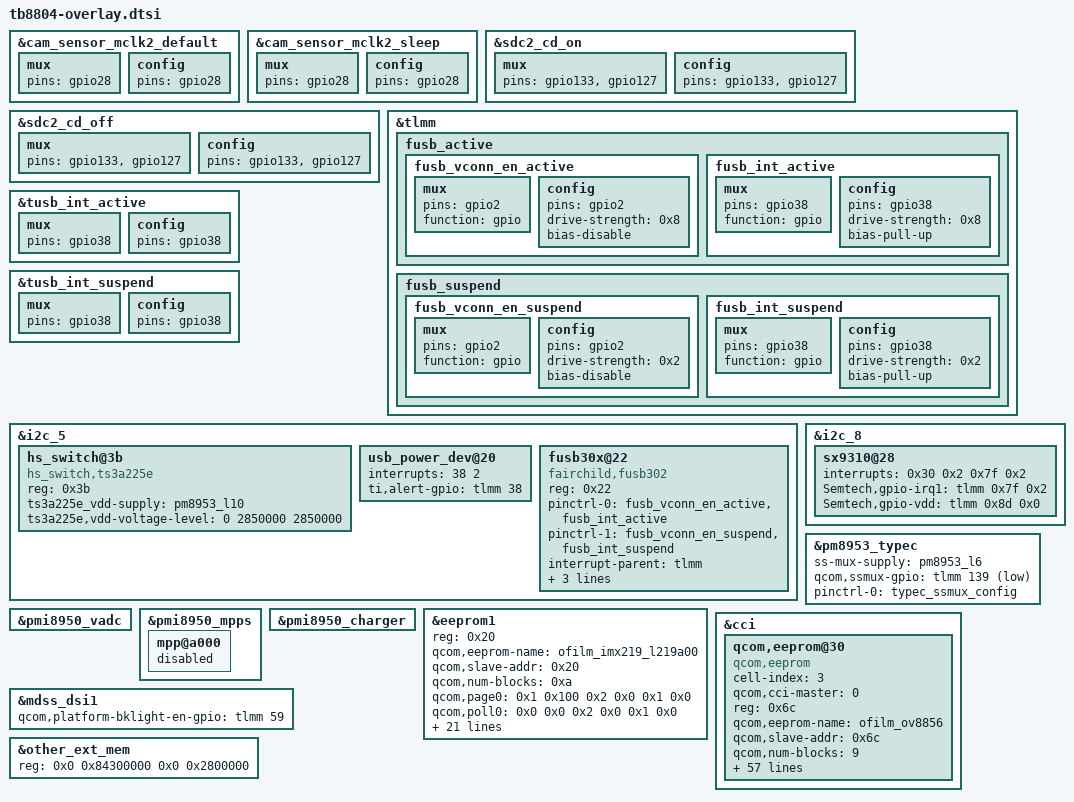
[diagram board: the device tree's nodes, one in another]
&cam_sensor_mclk2_default {
		mux {
				 pins = "gpio28";
		};
		config {
				 pins = "gpio28";
		};
};

&cam_sensor_mclk2_sleep {
		mux {
				 pins = "gpio28";
		};
		config {
				 pins = "gpio28";
		};


};

&sdc2_cd_on {
		mux {
				 pins = "gpio133", "gpio127";
		};
		config {
				 pins = "gpio133", "gpio127";
		};
};

&sdc2_cd_off {
		mux {
				 pins = "gpio133", "gpio127";
		};
		config {
				 pins = "gpio133", "gpio127";
		};
};


&tlmm {

		fusb_active {
				fusb_vconn_en_active: fusb_vconn_en_active {
						mux {
								pins = "gpio2";
								function = "gpio";
						};

						config {
								pins = "gpio2";
								drive-strength = <0x8>;
								bias-disable;
						};
				};

				fusb_int_active: fusb_int_active {

						mux {
								pins = "gpio38";
								function = "gpio";
						};

						config {
								pins = "gpio38";
								drive-strength = <0x8>;
								bias-pull-up;
						};
				};
		};

		fusb_suspend {

				fusb_vconn_en_suspend: fusb_vconn_en_suspend {
						mux {
								pins = "gpio2";
								function = "gpio";
						};

						config {
								pins = "gpio2";
								drive-strength = <0x2>;
								bias-disable;
						};
				};

				fusb_int_suspend: fusb_int_suspend {
						mux {
								pins = "gpio38";
								function = "gpio";
						};

						config {
								pins = "gpio38";
								drive-strength = <0x2>;
								bias-pull-up;
						};
				};
		};
};


&tusb_int_active {
		mux {
				pins = "gpio38";
		};
		config {
				pins = "gpio38";
		};
};

&tusb_int_suspend {
		mux {
				pins = "gpio38";
		};
		config {
				pins = "gpio38";
		};
};

&i2c_5 {
		status = "ok";
		hs_switch@3b {
				compatible = "hs_switch,ts3a225e";
				reg = <0x3b>;
				ts3a225e_vdd-supply = <&pm8953_l10>;
				ts3a225e,vdd-voltage-level = <0 2850000 2850000>;
		};
		usb_power_dev@20 {
				interrupts = <38 2>;
				ti,alert-gpio = <&tlmm 38 2>;
		};
		fusb30x@22 {
				compatible = "fairchild,fusb302";
				reg = <0x22>;
				status = "okay";
				pinctrl-names = "fusb_active", "fusb_suspend";
				pinctrl-0 = <&fusb_vconn_en_active &fusb_int_active>;
				pinctrl-1 = <&fusb_vconn_en_suspend &fusb_int_suspend>;
				interrupt-parent = <&tlmm>;
				interrupts = <38 2>;
				fairchild,vbus5v = <&pm8953_gpios 0x8 0x0>;
				fairchild,int_n = <&tlmm 38 2>;
		};
};

&i2c_8 {
		sx9310@28 {
				interrupts = <0x30 0x2  0x7f 0x2>;
				Semtech,gpio-irq1 = <&tlmm 0x7f 0x2>;
				Semtech,gpio-vdd = <&tlmm 0x8d 0x0>;
		};
};


&pm8953_typec {
		ss-mux-supply = <&pm8953_l6>;
		qcom,ssmux-gpio = <&tlmm 139 1>;
		pinctrl-names = "default";
		pinctrl-0 = <&typec_ssmux_config>;
};

&pmi8950_vadc {
		/delete-node/ chan@10;
};

&pmi8950_mpps {
		mpp@a000 {
				status = "disabled";
		};
};

&pmi8950_charger {
		/delete-property/ qcom,mpp1_adc-vadc;
		/delete-property/ qcom,usb_ss_sel;
		/delete-property/ pinctrl-names;
		/delete-property/ pinctrl-0;
};


&eeprom1 {
		reg = <0x20>;
		qcom,eeprom-name = "ofilm_imx219_l219a00";
		qcom,slave-addr = <0x20>;
		qcom,num-blocks = <0xa>;
		qcom,page0 = <0x1 0x100 0x2 0x0 0x1 0x0>;
		qcom,poll0 = <0x0 0x0 0x2 0x0 0x1 0x0>;
		qcom,page1 = <0x1 0x3302 0x2 0x2 0x1 0x0>;
		qcom,poll1 = <0x0 0x0 0x2 0x0 0x1 0x0>;
		qcom,page2 = <0x1 0x3303 0x2 0x58 0x1 0x0>;
		qcom,poll2 = <0x0 0x0 0x2 0x0 0x1 0x0>;
		qcom,page3 = <0x1 0x12a 0x2 0x18 0x1 0x0>;
		qcom,poll3 = <0x0 0x0 0x2 0x0 0x1 0x0>;
		qcom,page4 = <0x1 0x12b 0x2 0x0 0x1 0x0>;
		qcom,poll4 = <0x0 0x0 0x2 0x0 0x1 0x0>;
		qcom,page5 = <0x1 0x3300 0x2 0x8 0x1 0x0>;
		qcom,poll5 = <0x0 0x0 0x2 0x0 0x1 0x0>;
		qcom,page6 = <0x1 0x3200 0x2 0x1 0x1 0x1>;
		qcom,poll6 = <0x0 0x3201 0x2 0x1 0x1 0x0>;
		qcom,page7 = <0x1 0x3202 0x2 0x0 0x1 0x1>;
		qcom,poll7 = <0x0 0x3201 0x2 0x1 0x1 0x0>;
		qcom,mem7 = <0x40 0x3204 0x2 0x0 0x1 0x1>;
		qcom,page8 = <0x1 0x3202 0x2 0x1 0x1 0x1>;
		qcom,poll8 = <0x0 0x3201 0x2 0x1 0x1 0x0>;
		qcom,mem8 = <0x40 0x3204 0x2 0x0 0x1 0x1>;
		qcom,page9 = <0x1 0x3202 0x2 0x2 0x1 0x1>;
		qcom,poll9 = <0x0 0x3201 0x2 0x1 0x1 0x0>;
		qcom,mem9 = <0x40 0x3204 0x2 0x0 0x1 0x1>;
		/delete-property/ qcom,pageen8;
};

&cci {
 qcom,eeprom@30 {
                   cell-index = <3>;
                   compatible = "qcom,eeprom";
                   qcom,cci-master = <0>;
                   reg = <0x6c>;
   //add  jack  start
                   qcom,eeprom-name = "ofilm_ov8856"; //add
                   qcom,slave-addr = <0x6c>;          //add accoring to the camera address
                   qcom,num-blocks = <9>;             //add

                   qcom,page0 = <1 0x0100 2 0x01 1 1>;//add, write
                   qcom,poll0 = <0 0x0 2 0x0 1 1>;
                   qcom,mem0  = <0 0x0 2 0x0 1 0>;//read

                   qcom,page1 = <1 0x5001 2 0x02 1 1>;//modify
                   qcom,poll1 = <0 0x0 2 0x0 1 1>;
                   qcom,mem1  = <0 0x0 2 0x0 1 0>;

                   qcom,page2 = <1 0x3D84 2 0xC0 1 1>;//modify
	   qcom,poll2 = <0 0x0 2 0x0 1 1>;
	   qcom,mem2  = <0 0x0 2 0x0 1 0>;

	   qcom,page3 = <1 0x3D88 2 0x70 1 1>;
	   qcom,poll3 = <0 0x0 2 0x0 1 1>;
	   qcom,mem3  = <0 0x0 2 0x0 1 0>;

	   qcom,page4 = <1 0x3d89 2 0x10 1 1>;
	   qcom,poll4 = <0 0x0 2 0x0 1 1>;
	   qcom,mem4  = <0 0x0 2 0x0 1 0>;

	   qcom,page5 = <1 0x3d8A 2 0x72 1 0>;
	   qcom,poll5 = <0 0x0 2 0x0 1 1>;
	   qcom,mem5  = <0 0x0 2 0x0 1 0>;

	   qcom,page6 = <1 0x3D8B 2 0x0a 1 0x0a>;
	   qcom,poll6 = <0 0x0 2 0x0 1 1>;
	   qcom,mem6 =  <0 0x0 2 0x0 1 0>;

	    qcom,page7 = <1 0x3D81 2 0x01 1 10>;
	   qcom,poll7 = <0 0x0 2 0x0 1 1>;
	   qcom,mem7  = <512 0x7010 2 0x0 1 5>;

	    qcom,page8 = <1 20481 2 10 1 5>;
	   qcom,poll8 = <0 0x0 2 0x0 1 1>;
	   qcom,mem8  = <0 0 2 0 1 0>;
	   qcom,pageen8 = <0x1 0x100 0x2 0x0 0x1 0x5>;

                 cam_vdig-supply = <&pm8953_l2>;
                 cam_vana-supply = <&pm8953_l22>;
                 qcom,cam-vreg-name = "cam_vdig", "cam_vana";
                 qcom,cam-vreg-min-voltage = <1200000 0 2800000>;
                 qcom,cam-vreg-max-voltage = <1200000 0 2800000>;
                 qcom,cam-vreg-op-mode = <105000 0 80000>;
                 pinctrl-names = "cam_default", "cam_suspend";
                 pinctrl-0 = <&cam_sensor_mclk0_default
                                                 &cam_sensor_rear_default>;
                 pinctrl-1 = <&cam_sensor_mclk0_sleep &cam_sensor_rear_sleep>;
                 gpios = <&tlmm 26 0>,
                         <&tlmm 39 0>,
                         <&tlmm 130 0>;
                 qcom,gpio-reset = <1>;
                 qcom,sensor-mode = <0>;
                 qcom,gpio-vio = <2>;
                 qcom,gpio-req-tbl-num = <0 1 2>;
                 qcom,gpio-req-tbl-flags = <1 0 0>;
                 qcom,gpio-req-tbl-label = "CAMIF_MCLK0", "CAM_RESET0", "CAM_VIO";
                 qcom,cam-power-seq-type = "sensor_gpio", "sensor_vreg", "sensor_vreg", "sensor_clk", "sensor_gpio";
                 qcom,cam-power-seq-val =  "sensor_gpio_vio", "cam_vana", "cam_vdig", "sensor_cam_mclk", "sensor_gpio_reset";
                 qcom,cam-power-seq-cfg-val = <1 1 1 24000000 1>;
                 qcom,cam-power-seq-delay = <0 0 1 10 1>;
                 status = "ok";
                 clocks = <&clock_gcc clk_mclk0_clk_src>,
                                 <&clock_gcc clk_gcc_camss_mclk0_clk>;
                 clock-names = "cam_src_clk", "cam_clk";
                 qcom,clock-rates = <19200000 0>;
 };
};


&mdss_dsi1 {
		 qcom,platform-bklight-en-gpio = <&tlmm 59 0>;
};


&other_ext_mem {
		reg = <0x0 0x84300000 0x0 0x2800000>;
};
